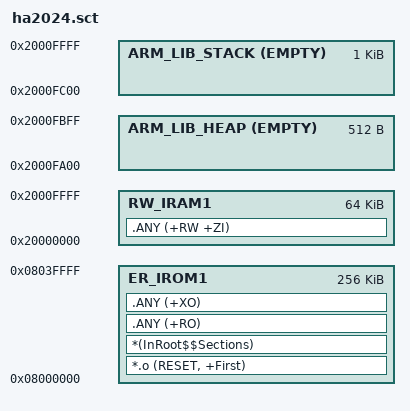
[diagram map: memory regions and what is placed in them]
; *************************************************************
; Scatter File for HA2024
; Generated: 2026-01-28 13:26:30
;
; Memory Map:
;   FLASH: 0x08000000 - 0x0803FFFF (256KB)
;   SRAM:  0x20000000 - 0x2000FFFF (64KB)
; *************************************************************

LR_IROM1 0x08000000 0x00040000  {    ; Load region - entire FLASH

  ER_IROM1 0x08000000 0x00040000  {  ; Execution region for code
    *.o (RESET, +First)                ; Vector table first
    *(InRoot$$Sections)                ; ARM library sections
    .ANY (+RO)                         ; All read-only code and data
    .ANY (+XO)                         ; Execute-only code
  }

  RW_IRAM1 0x20000000 0x00010000  {    ; RW data in SRAM
    .ANY (+RW +ZI)                     ; All read-write and zero-init data
  }

  ARM_LIB_HEAP  (0x20000000 + 0x0000FA00) EMPTY 0x00000200 {
    ; Heap region
  }

  ARM_LIB_STACK (0x20000000 + 0x00010000) EMPTY -0x00000400 {
    ; Stack region (grows downward)
  }
}
